VERSION ""

NS_ :

BS_:

BU_:

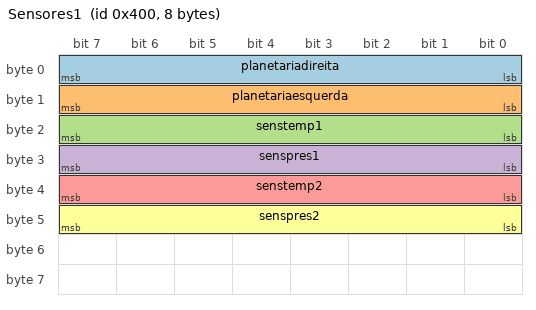
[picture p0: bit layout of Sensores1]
BO_ 1024 Sensores1: 8 Vector__XXX
 SG_ planetariadireita : 0|8@1+ (1,0) [0|0] "" Vector__XXX
 SG_ planetariaesquerda : 8|8@1+ (1,0) [0|0] "" Vector__XXX
 SG_ senstemp1 : 16|8@1+ (1,0) [0|0] "" Vector__XXX
 SG_ senspres1 : 24|8@1+ (1,0) [0|0] "" Vector__XXX
 SG_ senstemp2 : 32|8@1+ (1,0) [0|0] "" Vector__XXX
 SG_ senspres2 : 40|8@1+ (1,0) [0|0] "" Vector__XXX

BO_ 1025 sensores2: 8 Vector__XXX
 SG_ freio : 0|8@1+ (1,0) [0|0] "" Vector__XXX
 SG_ suspaR : 8|8@1+ (1,0) [0|0] "" Vector__XXX

BA_DEF_  "BusType" STRING ;
BA_DEF_DEF_  "BusType" "CAN";
